AUTOSAR XML (schema 4-2-2)
package /ComponentTypes
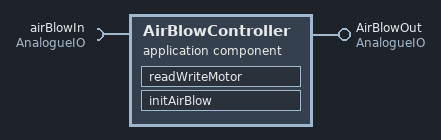
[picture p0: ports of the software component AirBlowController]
  application sw component type AirBlowController
    require port airBlowIn: nonqueued-receiver-com-spec{data-element=speed, init-value=0}, required-interface=AnalogueIO
    provide port AirBlowOut: nonqueued-sender-com-spec=speed, provided-interface=AnalogueIO
    behavior AirBlowController_InternalBehavior: data-type-mapping=speedMapSet
      data received event DRT_readWriteMotor_airBlowIn_speed: start-on-event=readWriteMotor, data=airBlowIn.speed
      init event AirBlowController_InitEvent: start-on-event=initAirBlow
      runnable readWriteMotor
        data-receive-point-by-arguments:
          access REC_airBlowIn_speed: accessed-variable=airBlowIn.speed
        data-send-points:
          access SEND_AirBlowOut_speed: accessed-variable=AirBlowOut.speed
      runnable initAirBlow
        data-receive-point-by-arguments:
          access REC_airBlowIn_speed: accessed-variable=airBlowIn.speed
        data-send-points:
          access SEND_AirBlowOut_speed: accessed-variable=AirBlowOut.speed
  swc implementation AirBlowController_Implementation: behavior=AirBlowController_InternalBehavior
